# STM32H730 register map
File version: 1.8
CPU: CM7 r0p1, little endian, MPU, FPU, 4 interrupt priority bits
Registers are 32-bit, read-write, reset 0x0 unless marked. A register's access mark holds for its fields unless they carry their own. Offsets are from the block's base; [hi:lo] are bit positions; {n}, {i} and the like mark numbered series.

## SYSCFG — System configuration controller
Base 0x58000400
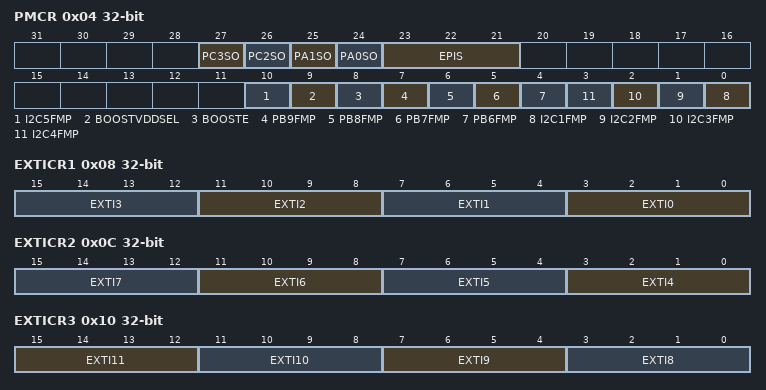
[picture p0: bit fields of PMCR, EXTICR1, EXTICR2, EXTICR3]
0x04 PMCR — peripheral mode configuration register
  [27] PC3SO — PC3 Switch Open
  [26] PC2SO — PC2 Switch Open
  [25] PA1SO — PA1 Switch Open
  [24] PA0SO — PA0 Switch Open
  [23:21] EPIS — Ethernet PHY Interface Selection
  [10] I2C5FMP — I2C5 Fm+
  [9] BOOSTVDDSEL — Analog switch supply voltage selection
  [8] BOOSTE — Booster Enable
  [7] PB9FMP — PB(9) Fm+
  [6] PB8FMP — PB(8) Fast Mode Plus
  [5] PB7FMP — PB(7) Fast Mode Plus
  [4] PB6FMP — PB(6) Fm+
  [n-1] I2C{n}FMP (n=1..4) — I2C{n} Fm+
0x08 EXTICR1 — external interrupt configuration register 1
  [4n+3:4n] EXTI{n} (n=0..3) — EXTI x configuration (x = 0 to 3)
0x0C EXTICR2 — external interrupt configuration register 2
  [4n-13:4n-16] EXTI{n} (n=4..7) — EXTI x configuration (x = 4 to 7)
0x10 EXTICR3 — external interrupt configuration register 3
  [15:12] EXTI11 — EXTI x configuration (x = 8 to 11)
  [11:8] EXTI10
  [7:4] EXTI9 — EXTI x configuration (x = 8 to 11)
  [3:0] EXTI8 — EXTI x configuration (x = 8 to 11)
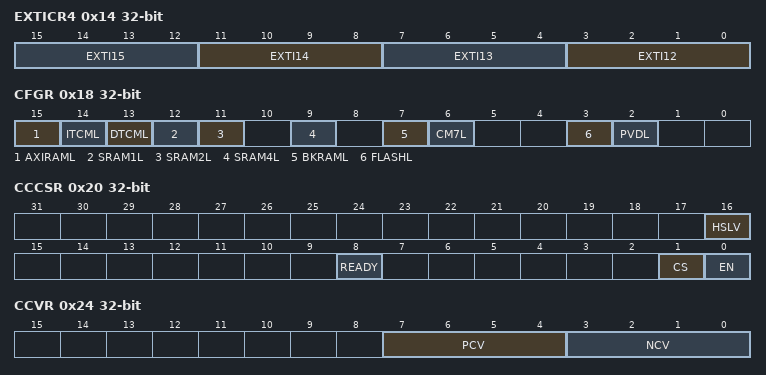
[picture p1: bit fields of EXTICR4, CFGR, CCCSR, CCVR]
0x14 EXTICR4 — external interrupt configuration register 4
  [4n-45:4n-48] EXTI{n} (n=12..15) — EXTI x configuration (x = 12 to 15)
0x18 CFGR access not given — Timer break lockup register
  [15] AXIRAML — AXISRAM Double error lockup bit
  [14] ITCML — ITCM-RAM Double error lockup bit
  [13] DTCML — DTCM-RAM Double error lockup bit
  [12] SRAM1L — SRAM1 Double error lockup bit
  [11] SRAM2L — SRAM2 Double error lockup bit
  [9] SRAM4L — SRAM4 Double error lockup bit
  [7] BKRAML — Backup RAM Double error lockup bit
  [6] CM7L — CPU lockup bit
  [3] FLASHL — FLASH double error lockup bit
  [2] PVDL — Programmable voltage detector lockup bit
0x20 CCCSR — compensation cell control/status register
  [16] HSLV — High-speed at low-voltage
  [8] READY — Compensation cell ready flag
  [1] CS — Code selection
  [0] EN — enable
0x24 CCVR ro — SYSCFG compensation cell value register
  [7:4] PCV — PMOS compensation value
  [3:0] NCV — NMOS compensation value
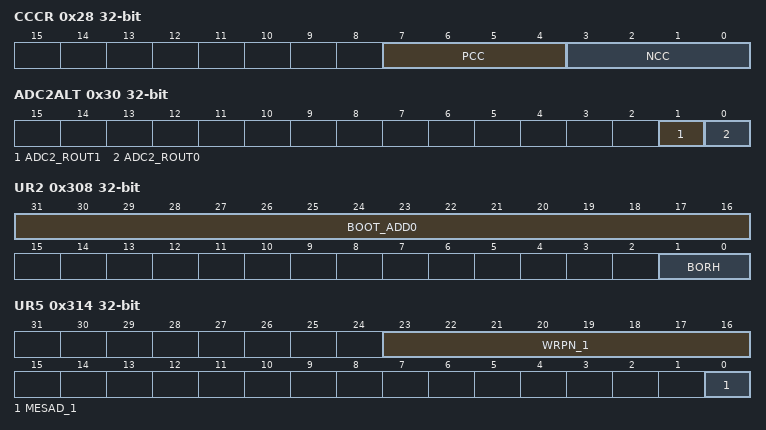
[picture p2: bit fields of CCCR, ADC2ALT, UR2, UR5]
0x28 CCCR — SYSCFG compensation cell code register
  [7:4] PCC — PMOS compensation code
  [3:0] NCC — NMOS compensation code
0x30 ADC2ALT access not given — ADC2 internal input alternate connection
  [1] ADC2_ROUT1 — ADC2 V_INP17 alternate connection
  [0] ADC2_ROUT0 — ADC2 V_INP16 alternate connection
0x124 PKGR ro — SYSCFG package register
  [3:0] PKG — Package
0x300 UR0 ro — SYSCFG user register 0
  [23:16] RDP — Readout protection
0x308 UR2 — SYSCFG user register 2
  [31:16] BOOT_ADD0 — Boot Address 0
  [1:0] BORH — BOR_LVL Brownout Reset Threshold Level
0x30C UR3 — SYSCFG user register 3
  [31:16] BOOT_ADD1 — Boot Address 1
0x310 UR4 ro — SYSCFG user register 4
  [16] MEPAD_1 — Mass Erase Protected Area Disabled for bank 1
0x314 UR5 ro — SYSCFG user register 5
  [23:16] WRPN_1 — Write protection for flash bank 1
  [0] MESAD_1 — Mass erase secured area disabled for bank 1
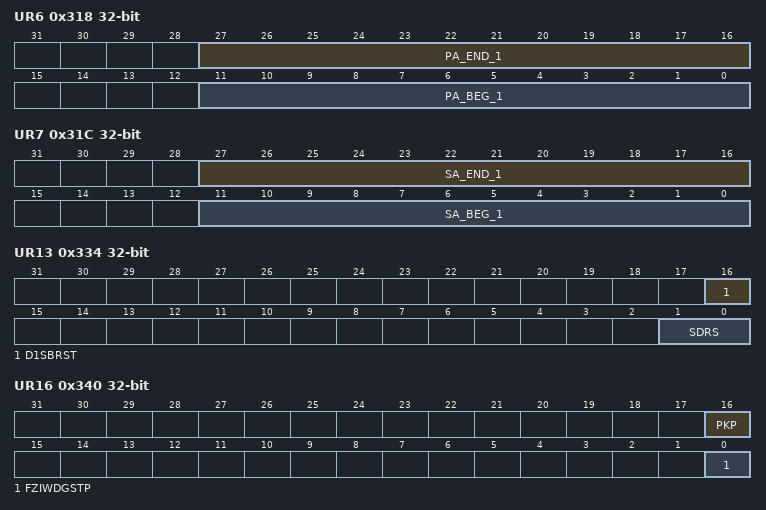
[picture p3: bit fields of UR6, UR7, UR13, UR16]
0x318 UR6 ro — SYSCFG user register 6
  [27:16] PA_END_1 — Protected area end address for bank 1
  [11:0] PA_BEG_1 — Protected area start address for bank 1
0x31C UR7 ro — SYSCFG user register 7
  [27:16] SA_END_1 — Secured area end address for bank 1
  [11:0] SA_BEG_1 — Secured area start address for bank 1
0x32C UR11 ro — SYSCFG user register 11
  [16] IWDG1M — Independent Watchdog 1 mode
0x330 UR12 ro — SYSCFG user register 12
  [16] SECURE — Secure mode
0x334 UR13 ro — SYSCFG user register 13
  [16] D1SBRST — D1 Standby reset
  [1:0] SDRS — Secured DTCM RAM Size
0x338 UR14 — SYSCFG user register 14
  [0] D1STPRST — D1 Stop Reset
0x33C UR15 ro — SYSCFG user register 15
  [16] FZIWDGSTB — Freeze independent watchdog in Standby mode
0x340 UR16 ro — SYSCFG user register 16
  [16] PKP — Private key programmed
  [0] FZIWDGSTP — Freeze independent watchdog in Stop mode
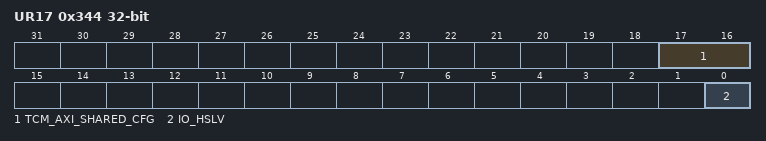
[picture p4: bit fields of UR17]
0x344 UR17 ro — SYSCFG user register 17
  [17:16] TCM_AXI_SHARED_CFG — ITCM-RAM/AXI-SRAM size
  [0] IO_HSLV — I/O high speed / low voltage
0x348 UR18 ro — SYSCFG user register 18
  [0] CPU_FREQ_BOOST — CPU maximum frequency boost
